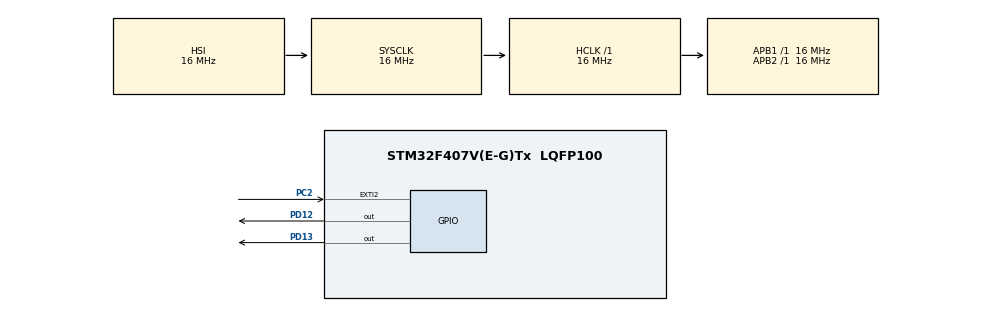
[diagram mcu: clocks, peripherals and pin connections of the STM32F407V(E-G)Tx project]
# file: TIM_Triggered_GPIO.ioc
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Mcu.Family=STM32F4
Mcu.Name=STM32F407V(E-G)Tx
Mcu.Package=LQFP100
NVIC.PriorityGroup=NVIC_PRIORITYGROUP_4
NVIC.TIM1_UP_TIM10_IRQn=true\:0\:0\:false\:false\:true\:true\:true
NVIC.TIM5_IRQn=true\:0\:0\:false\:false\:true\:true\:true
PC2.GPIO_PuPd=GPIO_PULLDOWN
PC2.Signal=GPXTI2
PD12.GPIO_PuPd=GPIO_PULLDOWN
PD12.Signal=GPIO_Output
PD13.GPIO_PuPd=GPIO_PULLDOWN
PD13.Signal=GPIO_Output
ProjectManager.HeapSize=0x200
ProjectManager.StackSize=0x400
ProjectManager.TargetToolchain=MDK-ARM V5.27
RCC.AHBFreq_Value=16000000
RCC.APB1Freq_Value=16000000
RCC.APB2Freq_Value=16000000
RCC.CortexFreq_Value=16000000
RCC.HSE_VALUE=25000000
RCC.HSI_VALUE=16000000
RCC.LSE_VALUE=32768
RCC.SYSCLKFreq_VALUE=16000000
RCC.VCOOutputFreq_Value=192000000
TIM1.Prescaler=16
TIM5.Period=65000
TIM5.Prescaler=7200
VP_TIM1_VS_ClockSourceINT.Mode=Internal
VP_TIM5_VS_ClockSourceINT.Mode=Internal
board=custom

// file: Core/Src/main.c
/* USER CODE BEGIN Header */
/**
  ******************************************************************************
  * @file           : main.c
  * @brief          : Main program body
  ******************************************************************************
  * @attention
  *
  * <h2><center>&copy; Copyright (c) 2020 STMicroelectronics.
  * All rights reserved.</center></h2>
  *
  * This software component is licensed by ST under BSD 3-Clause license,
  * the "License"; You may not use this file except in compliance with the
  * License. You may obtain a copy of the License at:
  *                        opensource.org/licenses/BSD-3-Clause
  *
  ******************************************************************************
  */
/* USER CODE END Header */
#include "main.h"

TIM_HandleTypeDef htim1;
TIM_HandleTypeDef htim5;

/* USER CODE BEGIN PV */
uint8_t i = 0;
uint8_t Status = 0;
/* USER CODE END PV */

void SystemClock_Config(void);
static void MX_GPIO_Init(void);
static void MX_TIM5_Init(void);
static void MX_TIM1_Init(void);

int main(void)
{

  /* MCU Configuration--------------------------------------------------------*/

  /* Reset of all peripherals, Initializes the Flash interface and the Systick. */
  HAL_Init();

  /* Configure the system clock */
  SystemClock_Config();

  /* Initialize all configured peripherals */
  MX_GPIO_Init();
  MX_TIM5_Init();
  MX_TIM1_Init();
  /* USER CODE BEGIN 2 */
	HAL_TIM_Base_Start_IT(&htim1);
  /* USER CODE END 2 */

  /* Infinite loop */
  while (1)
  {

  }
}

void SystemClock_Config(void)
{
  RCC_OscInitTypeDef RCC_OscInitStruct = {0};
  RCC_ClkInitTypeDef RCC_ClkInitStruct = {0};

  /** Configure the main internal regulator output voltage
  */
  __HAL_RCC_PWR_CLK_ENABLE();
  __HAL_PWR_VOLTAGESCALING_CONFIG(PWR_REGULATOR_VOLTAGE_SCALE1);
  /** Initializes the RCC Oscillators according to the specified parameters
  * in the RCC_OscInitTypeDef structure.
  */
  RCC_OscInitStruct.OscillatorType = RCC_OSCILLATORTYPE_HSI;
  RCC_OscInitStruct.HSIState = RCC_HSI_ON;
  RCC_OscInitStruct.HSICalibrationValue = RCC_HSICALIBRATION_DEFAULT;
  RCC_OscInitStruct.PLL.PLLState = RCC_PLL_NONE;
  if (HAL_RCC_OscConfig(&RCC_OscInitStruct) != HAL_OK)
  {
    Error_Handler();
  }
  /** Initializes the CPU, AHB and APB buses clocks
  */
  RCC_ClkInitStruct.ClockType = RCC_CLOCKTYPE_HCLK|RCC_CLOCKTYPE_SYSCLK
                              |RCC_CLOCKTYPE_PCLK1|RCC_CLOCKTYPE_PCLK2;
  RCC_ClkInitStruct.SYSCLKSource = RCC_SYSCLKSOURCE_HSI;
  RCC_ClkInitStruct.AHBCLKDivider = RCC_SYSCLK_DIV1;
  RCC_ClkInitStruct.APB1CLKDivider = RCC_HCLK_DIV1;
  RCC_ClkInitStruct.APB2CLKDivider = RCC_HCLK_DIV1;

  if (HAL_RCC_ClockConfig(&RCC_ClkInitStruct, FLASH_LATENCY_0) != HAL_OK)
  {
    Error_Handler();
  }
}

static void MX_TIM1_Init(void)
{

  TIM_ClockConfigTypeDef sClockSourceConfig = {0};
  TIM_MasterConfigTypeDef sMasterConfig = {0};

  htim1.Instance = TIM1;
  htim1.Init.Prescaler = 16;
  htim1.Init.CounterMode = TIM_COUNTERMODE_UP;
  htim1.Init.Period = 65535;
  htim1.Init.ClockDivision = TIM_CLOCKDIVISION_DIV1;
  htim1.Init.RepetitionCounter = 0;
  htim1.Init.AutoReloadPreload = TIM_AUTORELOAD_PRELOAD_DISABLE;
  if (HAL_TIM_Base_Init(&htim1) != HAL_OK)
  {
    Error_Handler();
  }
  sClockSourceConfig.ClockSource = TIM_CLOCKSOURCE_INTERNAL;
  if (HAL_TIM_ConfigClockSource(&htim1, &sClockSourceConfig) != HAL_OK)
  {
    Error_Handler();
  }
  sMasterConfig.MasterOutputTrigger = TIM_TRGO_RESET;
  sMasterConfig.MasterSlaveMode = TIM_MASTERSLAVEMODE_DISABLE;
  if (HAL_TIMEx_MasterConfigSynchronization(&htim1, &sMasterConfig) != HAL_OK)
  {
    Error_Handler();
  }

}

static void MX_TIM5_Init(void)
{

  TIM_ClockConfigTypeDef sClockSourceConfig = {0};
  TIM_MasterConfigTypeDef sMasterConfig = {0};

  htim5.Instance = TIM5;
  htim5.Init.Prescaler = 7200;
  htim5.Init.CounterMode = TIM_COUNTERMODE_UP;
  htim5.Init.Period = 65000;
  htim5.Init.ClockDivision = TIM_CLOCKDIVISION_DIV1;
  htim5.Init.AutoReloadPreload = TIM_AUTORELOAD_PRELOAD_DISABLE;
  if (HAL_TIM_Base_Init(&htim5) != HAL_OK)
  {
    Error_Handler();
  }
  sClockSourceConfig.ClockSource = TIM_CLOCKSOURCE_INTERNAL;
  if (HAL_TIM_ConfigClockSource(&htim5, &sClockSourceConfig) != HAL_OK)
  {
    Error_Handler();
  }
  sMasterConfig.MasterOutputTrigger = TIM_TRGO_RESET;
  sMasterConfig.MasterSlaveMode = TIM_MASTERSLAVEMODE_DISABLE;
  if (HAL_TIMEx_MasterConfigSynchronization(&htim5, &sMasterConfig) != HAL_OK)
  {
    Error_Handler();
  }

}

static void MX_GPIO_Init(void)
{
  GPIO_InitTypeDef GPIO_InitStruct = {0};

  /* GPIO Ports Clock Enable */
  __HAL_RCC_GPIOC_CLK_ENABLE();
  __HAL_RCC_GPIOD_CLK_ENABLE();

  /*Configure GPIO pin Output Level */
  HAL_GPIO_WritePin(GPIOD, GPIO_PIN_12|GPIO_PIN_13, GPIO_PIN_RESET);

  /*Configure GPIO pin : PC2 */
  GPIO_InitStruct.Pin = GPIO_PIN_2;
  GPIO_InitStruct.Mode = GPIO_MODE_IT_RISING;
  GPIO_InitStruct.Pull = GPIO_PULLDOWN;
  HAL_GPIO_Init(GPIOC, &GPIO_InitStruct);

  /*Configure GPIO pins : PD12 PD13 */
  GPIO_InitStruct.Pin = GPIO_PIN_12|GPIO_PIN_13;
  GPIO_InitStruct.Mode = GPIO_MODE_OUTPUT_PP;
  GPIO_InitStruct.Pull = GPIO_PULLDOWN;
  GPIO_InitStruct.Speed = GPIO_SPEED_FREQ_LOW;
  HAL_GPIO_Init(GPIOD, &GPIO_InitStruct);

}

/* USER CODE BEGIN 4 */
void HAL_TIM_PeriodElapsedCallback(TIM_HandleTypeDef *htim)
{
Status = 1;
	if(htim->Instance == TIM1){
		if (HAL_GPIO_ReadPin(GPIOC, GPIO_PIN_2) == SET)
	{HAL_GPIO_WritePin(GPIOD, GPIO_PIN_12, GPIO_PIN_SET) ;
	 HAL_Delay(100);
	HAL_GPIO_TogglePin(GPIOD, GPIO_PIN_12);
		HAL_Delay(100);
	HAL_GPIO_TogglePin(GPIOD, GPIO_PIN_12);
	Status = 0;
	}
	else if
 (HAL_GPIO_ReadPin(GPIOC, GPIO_PIN_2) == RESET)
	{HAL_GPIO_WritePin(GPIOD, GPIO_PIN_12, GPIO_PIN_SET) ;
	 HAL_Delay(100);
	HAL_GPIO_TogglePin(GPIOD, GPIO_PIN_12);
		HAL_Delay(100);
	HAL_GPIO_TogglePin(GPIOD, GPIO_PIN_12);
	Status = 0; }
	}
}

/* USER CODE END 4 */

void Error_Handler(void)
{
}

/************************ (C) COPYRIGHT STMicroelectronics *****END OF FILE****/
